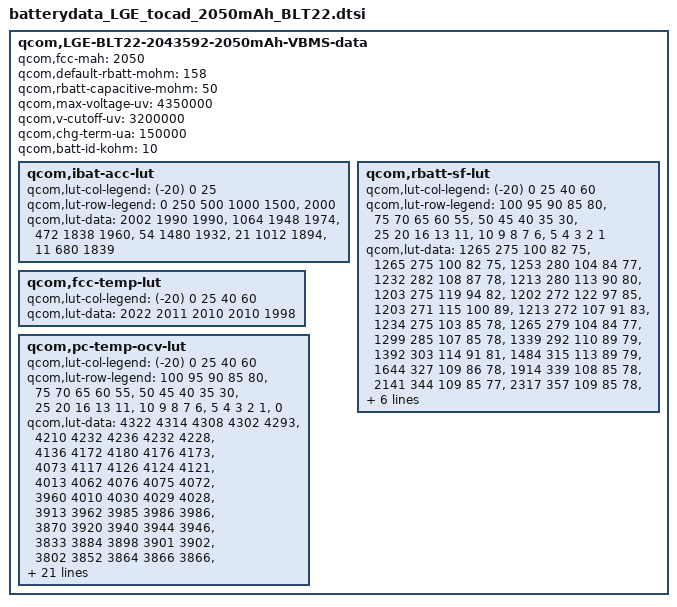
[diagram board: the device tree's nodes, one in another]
/* Copyright (c) 2015, The Linux Foundation. All rights reserved.
 *
 * This program is free software; you can redistribute it and/or modify
 * it under the terms of the GNU General Public License version 2 and
 * only version 2 as published by the Free Software Foundation.
 *
 * This program is distributed in the hope that it will be useful,
 * but WITHOUT ANY WARRANTY; without even the implied warranty of
 * MERCHANTABILITY or FITNESS FOR A PARTICULAR PURPOSE.  See the
 * GNU General Public License for more details.
 */
 qcom,LGE-BLT22-2043592-2050mAh-VBMS-data {
	qcom,fcc-mah = <2050>;
	qcom,default-rbatt-mohm = <158>;
	qcom,rbatt-capacitive-mohm = <50>;
	qcom,max-voltage-uv = <4350000>;
	qcom,v-cutoff-uv = <3200000>;
	qcom,chg-term-ua = <150000>;
	qcom,batt-id-kohm = <10>;

	qcom,ibat-acc-lut {
		qcom,lut-col-legend = <(-20) 0 25>;
		qcom,lut-row-legend = <0 250 500 1000 1500>,
				<2000>;
		qcom,lut-data = <2002 1990 1990>,
				<1064 1948 1974>,
				<472 1838 1960>,
				<54 1480 1932>,
				<21 1012 1894>,
				<11 680 1839>;
	};

	qcom,rbatt-sf-lut {
		qcom,lut-col-legend = <(-20) 0 25 40 60>;
		qcom,lut-row-legend = <100 95 90 85 80>,
				<75 70 65 60 55>,
				<50 45 40 35 30>,
				<25 20 16 13 11>,
				<10 9 8 7 6>,
				<5 4 3 2 1>;
		qcom,lut-data = <1265 275 100 82 75>,
				<1265 275 100 82 75>,
				<1253 280 104 84 77>,
				<1232 282 108 87 78>,
				<1213 280 113 90 80>,
				<1203 275 119 94 82>,
				<1202 272 122 97 85>,
				<1203 271 115 100 89>,
				<1213 272 107 91 83>,
				<1234 275 103 85 78>,
				<1265 279 104 84 77>,
				<1299 285 107 85 78>,
				<1339 292 110 89 79>,
				<1392 303 114 91 81>,
				<1484 315 113 89 79>,
				<1644 327 109 86 78>,
				<1914 339 108 85 78>,
				<2141 344 109 85 77>,
				<2317 357 109 85 78>,
				<2423 375 111 86 78>,
				<2466 384 113 87 79>,
				<2122 383 115 88 80>,
				<2275 367 115 88 80>,
				<2733 386 116 87 78>,
				<3424 414 112 85 78>,
				<4640 451 113 87 78>,
				<6920 515 116 89 80>,
				<13457 667 123 91 82>,
				<26914 1165 135 96 90>,
				<53828 2330 181 119 128>;
	};

	qcom,fcc-temp-lut {
		qcom,lut-col-legend = <(-20) 0 25 40 60>;
		qcom,lut-data = <2022 2011 2010 2010 1998>;
	};

	qcom,pc-temp-ocv-lut {
		qcom,lut-col-legend = <(-20) 0 25 40 60>;
		qcom,lut-row-legend = <100 95 90 85 80>,
				<75 70 65 60 55>,
				<50 45 40 35 30>,
				<25 20 16 13 11>,
				<10 9 8 7 6>,
				<5 4 3 2 1>,
				<0>;
		qcom,lut-data = <4322 4314 4308 4302 4293>,
				<4210 4232 4236 4232 4228>,
				<4136 4172 4180 4176 4173>,
				<4073 4117 4126 4124 4121>,
				<4013 4062 4076 4075 4072>,
				<3960 4010 4030 4029 4028>,
				<3913 3962 3985 3986 3986>,
				<3870 3920 3940 3944 3946>,
				<3833 3884 3898 3901 3902>,
				<3802 3852 3864 3866 3866>,
				<3776 3826 3838 3838 3838>,
				<3754 3802 3816 3816 3816>,
				<3734 3783 3796 3798 3798>,
				<3715 3768 3780 3782 3782>,
				<3698 3756 3764 3762 3756>,
				<3680 3742 3746 3740 3730>,
				<3660 3722 3724 3719 3708>,
				<3639 3697 3704 3698 3687>,
				<3616 3677 3686 3682 3670>,
				<3596 3664 3674 3672 3663>,
				<3584 3657 3670 3669 3660>,
				<3574 3649 3666 3666 3656>,
				<3558 3640 3660 3660 3650>,
				<3539 3628 3648 3646 3634>,
				<3514 3609 3620 3618 3602>,
				<3486 3574 3578 3578 3560>,
				<3444 3524 3524 3524 3508>,
				<3390 3453 3455 3456 3440>,
				<3312 3362 3369 3371 3351>,
				<3189 3224 3230 3238 3217>,
				<3000 3000 3000 3000 3000>;
	};
};
